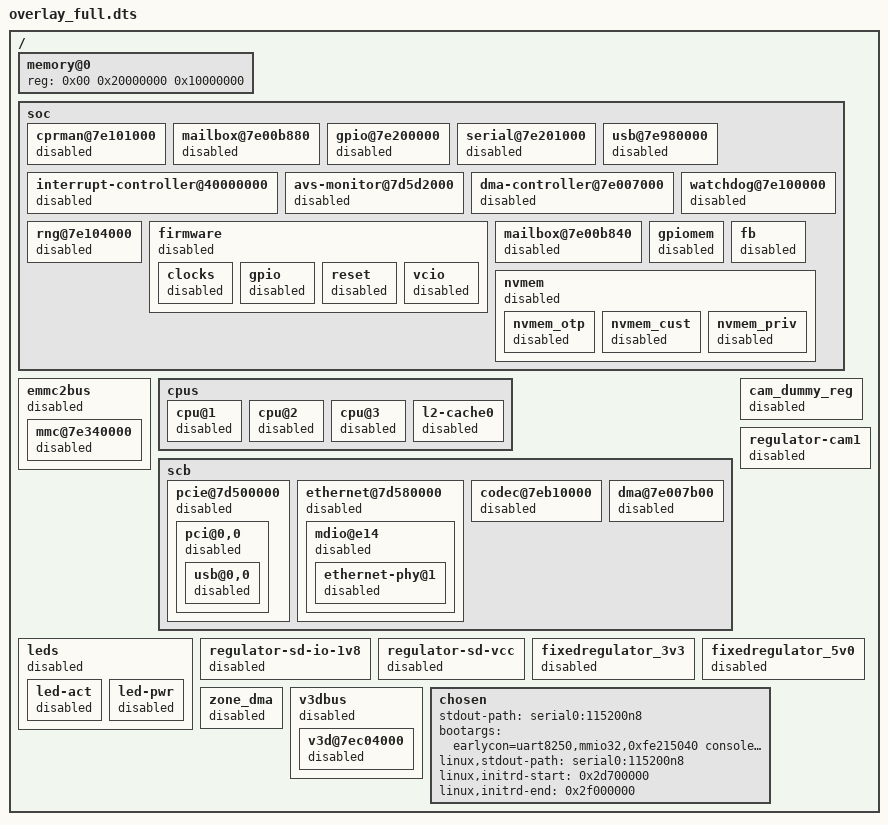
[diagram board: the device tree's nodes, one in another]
/ {
     memory@0 {
		device_type = "memory";
          /* Tell Linux that only 256MiB of RAM is available starting at 0x20000000 (to avoid collision). */
		reg = <0x00 0x20000000 0x10000000>;
     };

     soc {
          cprman@7e101000 {
               status = "disabled";
          };

          mailbox@7e00b880 {
			status = "disabled";
		};

          gpio@7e200000 {
               status = "disabled";
          };

		serial@7e201000 {
			status = "disabled";
		};

		usb@7e980000 {
			status = "disabled";
		};

		interrupt-controller@40000000 {
			status = "disabled";
		};

		avs-monitor@7d5d2000 {
			status = "disabled";
		};

		dma-controller@7e007000 {
			status = "disabled";
		};

		watchdog@7e100000 {
			status = "disabled";
		};

		rng@7e104000 {
			status = "disabled";
		};

          firmware {
			status = "disabled";

			clocks {
				status = "disabled";
			};

			gpio {
				status = "disabled";
			};

			reset {
				status = "disabled";
			};

			vcio {
				status = "disabled";
			};
		};

		mailbox@7e00b840 {
			status = "disabled";
		};

		gpiomem {
			status = "disabled";
		};

          fb {
			status = "disabled";
		};

		nvmem {
			status = "disabled";
			nvmem_otp {
				status = "disabled";
			};
			nvmem_cust {
				status = "disabled";
			};
			nvmem_priv {
				status = "disabled";
			};
		};
     };

	emmc2bus {
		status = "disabled";
		mmc@7e340000 {
			status = "disabled";
		};
	};

     cpus {

		cpu@1 {
			status = "disabled";
		};

		cpu@2 {
			status = "disabled";
		};

		cpu@3 {
			status = "disabled";
		};

		l2-cache0 {
			status = "disabled";
		};
	};

     scb {
		pcie@7d500000 {
			status = "disabled";
			pci@0,0 {
				status = "disabled";

				usb@0,0 {
					status = "disabled";
				};
			};
		};
		ethernet@7d580000 {
			status = "disabled";
			mdio@e14 {
				status = "disabled";
				ethernet-phy@1 {
					status = "disabled";
				};
			};
		};
		codec@7eb10000 {
			status = "disabled";
		};
		dma@7e007b00 {
			status = "disabled";
		};
	};

     leds {
		status = "disabled";
		led-act {
			status = "disabled";
		};
		led-pwr {
			status = "disabled";
		};
	};

	cam_dummy_reg {
          status = "disabled";
	};

     regulator-cam1 {
		status = "disabled";
	};

	regulator-sd-io-1v8 {
		status = "disabled";
	};

	regulator-sd-vcc {
		status = "disabled";
	};

	fixedregulator_3v3 {
		status = "disabled";
	};

	fixedregulator_5v0 {
		status = "disabled";
	};

	zone_dma {
		status = "disabled";
	};

	v3dbus {
		status = "disabled";
		v3d@7ec04000 {
			status = "disabled";
		};
	};


     chosen {
		stdout-path = "serial0:115200n8";
		bootargs = "earlycon=uart8250,mmio32,0xfe215040 console=serial0,115200 debug loglevel=8 maxcpus=1";
          linux,stdout-path = "serial0:115200n8";
          linux,initrd-start = <0x2d700000>;
          linux,initrd-end = <0x2f000000>;
	};
};
